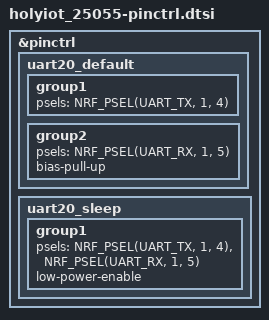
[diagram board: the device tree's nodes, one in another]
/*
 * SPDX-License-Identifier: Apache-2.0
 *
 * Holyiot 25055 pin assignments:
 *   TXD = P1.04 (AIN0)
 *   RXD = P1.05 (AIN1)
 *
 * BEEP/buzzer = P1.06 (AIN2) — driven directly via GPIO
 *   (no PWM pinctrl needed; gpio-leds compatible declared in board common dtsi).
 */

&pinctrl {
	/omit-if-no-ref/ uart20_default: uart20_default {
		group1 {
			psels = <NRF_PSEL(UART_TX, 1, 4)>;
		};
		group2 {
			psels = <NRF_PSEL(UART_RX, 1, 5)>;
			bias-pull-up;
		};
	};

	/omit-if-no-ref/ uart20_sleep: uart20_sleep {
		group1 {
			psels = <NRF_PSEL(UART_TX, 1, 4)>,
				<NRF_PSEL(UART_RX, 1, 5)>;
			low-power-enable;
		};
	};
};
